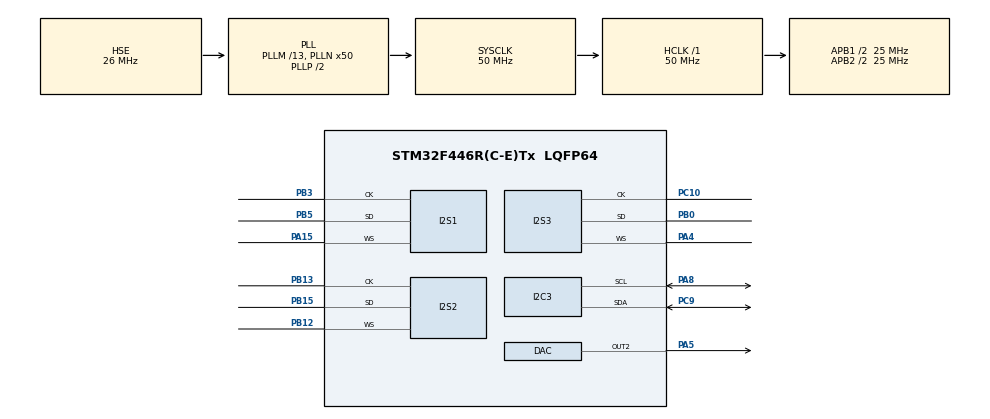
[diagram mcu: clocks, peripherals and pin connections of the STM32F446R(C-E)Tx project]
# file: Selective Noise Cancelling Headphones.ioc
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DAC.DAC_Trigger2=DAC_TRIGGER_NONE
Dma.DAC2.1.Direction=DMA_MEMORY_TO_PERIPH
Dma.DAC2.1.FIFOMode=DMA_FIFOMODE_DISABLE
Dma.DAC2.1.Instance=DMA1_Stream6
Dma.DAC2.1.MemDataAlignment=DMA_MDATAALIGN_HALFWORD
Dma.DAC2.1.MemInc=DMA_MINC_ENABLE
Dma.DAC2.1.Mode=DMA_CIRCULAR
Dma.DAC2.1.PeriphDataAlignment=DMA_PDATAALIGN_HALFWORD
Dma.DAC2.1.PeriphInc=DMA_PINC_DISABLE
Dma.DAC2.1.Priority=DMA_PRIORITY_HIGH
Dma.Request0=SPI3_RX
Dma.Request1=DAC2
Dma.Request2=SPI2_RX
Dma.SPI2_RX.2.Direction=DMA_PERIPH_TO_MEMORY
Dma.SPI2_RX.2.FIFOMode=DMA_FIFOMODE_DISABLE
Dma.SPI2_RX.2.Instance=DMA1_Stream3
Dma.SPI2_RX.2.MemDataAlignment=DMA_MDATAALIGN_HALFWORD
Dma.SPI2_RX.2.MemInc=DMA_MINC_ENABLE
Dma.SPI2_RX.2.Mode=DMA_CIRCULAR
Dma.SPI2_RX.2.PeriphDataAlignment=DMA_PDATAALIGN_HALFWORD
Dma.SPI2_RX.2.PeriphInc=DMA_PINC_DISABLE
Dma.SPI2_RX.2.Priority=DMA_PRIORITY_HIGH
Dma.SPI3_RX.0.Direction=DMA_PERIPH_TO_MEMORY
Dma.SPI3_RX.0.FIFOMode=DMA_FIFOMODE_DISABLE
Dma.SPI3_RX.0.Instance=DMA1_Stream0
Dma.SPI3_RX.0.MemDataAlignment=DMA_MDATAALIGN_HALFWORD
Dma.SPI3_RX.0.MemInc=DMA_MINC_ENABLE
Dma.SPI3_RX.0.Mode=DMA_CIRCULAR
Dma.SPI3_RX.0.PeriphDataAlignment=DMA_PDATAALIGN_HALFWORD
Dma.SPI3_RX.0.PeriphInc=DMA_PINC_DISABLE
Dma.SPI3_RX.0.Priority=DMA_PRIORITY_HIGH
I2S1.AudioFreq=I2S_AUDIOFREQ_48K
I2S1.DataFormat=I2S_DATAFORMAT_16B_EXTENDED
I2S1.ErrorAudioFreq=1.72 %
I2S1.FullDuplexMode=I2S_FULLDUPLEXMODE_DISABLE
I2S1.Instance=SPI$Index
I2S1.Mode=I2S_MODE_MASTER_RX
I2S1.RealAudioFreq=48.828 KHz
I2S1.VirtualMode=I2S_MODE_MASTER
I2S2.AudioFreq=I2S_AUDIOFREQ_48K
I2S2.DataFormat=I2S_DATAFORMAT_16B_EXTENDED
I2S2.ErrorAudioFreq=1.72 %
I2S2.FullDuplexMode=I2S_FULLDUPLEXMODE_DISABLE
I2S2.Instance=SPI$Index
I2S2.Mode=I2S_MODE_MASTER_RX
I2S2.RealAudioFreq=48.828 KHz
I2S2.VirtualMode=I2S_MODE_MASTER
I2S3.AudioFreq=I2S_AUDIOFREQ_48K
I2S3.DataFormat=I2S_DATAFORMAT_16B_EXTENDED
I2S3.ErrorAudioFreq=1.72 %
I2S3.FullDuplexMode=I2S_FULLDUPLEXMODE_DISABLE
I2S3.Instance=SPI$Index
I2S3.Mode=I2S_MODE_MASTER_RX
I2S3.RealAudioFreq=48.828 KHz
I2S3.VirtualMode=I2S_MODE_MASTER
Mcu.Family=STM32F4
Mcu.Name=STM32F446R(C-E)Tx
Mcu.Package=LQFP64
NVIC.DMA1_Stream0_IRQn=true\:0\:0\:false\:false\:true\:false\:true\:true
NVIC.DMA1_Stream3_IRQn=true\:0\:0\:false\:false\:true\:false\:true\:true
NVIC.DMA1_Stream6_IRQn=true\:0\:0\:false\:false\:true\:false\:true\:true
NVIC.PriorityGroup=NVIC_PRIORITYGROUP_4
NVIC.TIM2_IRQn=true\:15\:0\:false\:false\:true\:false\:true\:true
NVIC.TimeBase=TIM2_IRQn
NVIC.TimeBaseIP=TIM2
PA13.Mode=Serial_Wire
PA13.Signal=SYS_JTMS-SWDIO
PA14.Mode=Serial_Wire
PA14.Signal=SYS_JTCK-SWCLK
PA15.Mode=Half_Duplex_Master
PA15.Signal=I2S1_WS
PA4.Mode=Half_Duplex_Master
PA4.Signal=I2S3_WS
PA5.Signal=COMP_DAC2_group
PA8.Mode=I2C
PA8.Signal=I2C3_SCL
PB0.Mode=Half_Duplex_Master
PB0.Signal=I2S3_SD
PB12.Mode=Half_Duplex_Master
PB12.Signal=I2S2_WS
PB13.Mode=Half_Duplex_Master
PB13.Signal=I2S2_CK
PB15.Mode=Half_Duplex_Master
PB15.Signal=I2S2_SD
PB3.Mode=Half_Duplex_Master
PB3.Signal=I2S1_CK
PB5.Mode=Half_Duplex_Master
PB5.Signal=I2S1_SD
PC10.Mode=Half_Duplex_Master
PC10.Signal=I2S3_CK
PC9.Mode=I2C
PC9.Signal=I2C3_SDA
PH0-OSC_IN.Mode=HSE-External-Oscillator
PH0-OSC_IN.Signal=RCC_OSC_IN
PH1-OSC_OUT.Mode=HSE-External-Oscillator
PH1-OSC_OUT.Signal=RCC_OSC_OUT
ProjectManager.HeapSize=0x400
ProjectManager.StackSize=0x400
ProjectManager.TargetToolchain=STM32CubeIDE
RCC.AHBFreq_Value=50000000
RCC.APB1CLKDivider=RCC_HCLK_DIV2
RCC.APB1Freq_Value=25000000
RCC.APB1TimFreq_Value=50000000
RCC.APB2CLKDivider=RCC_HCLK_DIV2
RCC.APB2Freq_Value=25000000
RCC.APB2TimFreq_Value=50000000
RCC.CortexFreq_Value=50000000
RCC.HCLKFreq_Value=50000000
RCC.HSE_VALUE=26000000
RCC.PLLI2SM=13
RCC.PLLI2SN=50
RCC.PLLM=13
RCC.PLLN=50
RCC.PLLQ=4
RCC.PLLSourceVirtual=RCC_PLLSOURCE_HSE
RCC.SYSCLKFreq_VALUE=50000000
RCC.SYSCLKSource=RCC_SYSCLKSOURCE_PLLCLK
RCC.USBFreq_Value=25000000
RCC.VCOOutputFreq_Value=100000000
SH.COMP_DAC2_group.0=DAC_OUT2,DAC_OUT2
VP_SYS_VS_tim2.Mode=TIM2
board=custom

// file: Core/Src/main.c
/* USER CODE BEGIN Header */
/**
  ******************************************************************************
  * @file           : main.c
  * @brief          : Main program body
  ******************************************************************************
  * @attention
  *
  * Copyright (c) 2025 STMicroelectronics.
  * All rights reserved.
  *
  * This software is licensed under terms that can be found in the LICENSE file
  * in the root directory of this software component.
  * If no LICENSE file comes with this software, it is provided AS-IS.
  *
  ******************************************************************************
  */
/* USER CODE END Header */
#include "main.h"

/* USER CODE BEGIN Includes */

#include <stdio.h>
#include <stdlib.h>
#include "ADC.h"
#include "Delay.h"
#include "LowPass_FirstOrder.h"
#include "HighPass_FirstOrder.h"
#include "PeakingFilter.h"
#include "math.h"

/* USER CODE END Includes */

/* USER CODE BEGIN PM */

#define BUFFER_SIZE 128
#define INT16_TO_FLOAT (1.0f/32768.0f)
#define FLOAT_TO_INT16 32768.0f
#define SAMPLING_RATE 	48000
#define SIN_FREQ		1000
#define BUFFER_LENGTH 	SAMPLING_RATE / SIN_FREQ
#define VOLUME 50

/* USER CODE END PM */

DAC_HandleTypeDef hdac;
DMA_HandleTypeDef hdma_dac2;

I2C_HandleTypeDef hi2c3;

I2S_HandleTypeDef hi2s1;
I2S_HandleTypeDef hi2s2;
I2S_HandleTypeDef hi2s3;
DMA_HandleTypeDef hdma_spi2_rx;
DMA_HandleTypeDef hdma_spi3_rx;

/* USER CODE BEGIN PV */

int16_t inData[BUFFER_SIZE] __attribute__((aligned(4)));

static volatile int16_t *inBufPtr;

uint16_t dac_value;
uint16_t dataReadyFlag = 0;

//HighPass_FirstOrder hpFilt;
//LowPass_FirstOrder lpFilt;
EQ eq;
Delay dly;

/* USER CODE END PV */

void SystemClock_Config(void);
void PeriphCommonClock_Config(void);
static void MX_GPIO_Init(void);
static void MX_DMA_Init(void);
static void MX_DAC_Init(void);
static void MX_I2C3_Init(void);
static void MX_I2S3_Init(void);
static void MX_I2S2_Init(void);
static void MX_I2S1_Init(void);

/* USER CODE BEGIN 0 */

void HAL_I2S_RxHalfCpltCallback(I2S_HandleTypeDef *hi2s) {
	inBufPtr = &inData[0];
	dataReadyFlag = 1;

}

void HAL_I2S_RxCpltCallback(I2S_HandleTypeDef *hi2s) {
	inBufPtr = &inData[BUFFER_SIZE/2];
	dataReadyFlag = 1;
}

void processDataNoDelay() {

	float left;

	for (uint8_t n = 0; n < (BUFFER_SIZE/2) - 1; n += 1) {
		left = (inBufPtr[n] * INT16_TO_FLOAT);// + 0.0537;

		if (left > 1.0f) {
			left = 1.0f;
		}
		else if (left < -1.0f) {
			left = -1.0f;
		}

		//left = LowPass_FirstOrder_Update(&lpFilt, left);
		//left = HighPass_FirstOrder_Update(&hpFilt, left);

		dac_value = (int16_t)(left * 2047.0f * VOLUME) + 2048;
		HAL_DAC_SetValue(&hdac, DAC_CHANNEL_2, DAC_ALIGN_12B_R, dac_value);

	}

}

void processData(LowPass_FirstOrder *lpFilt, HighPass_FirstOrder *hpFilt) {

	static float left;
	static float right;
	static float rightDelayed;
	static float out;

	int16_t leftInverted;
	int16_t rightInverted;
	uint16_t leftInvertedShift;
	uint16_t rightInvertedShift;

	for (uint8_t n = 0; n < (BUFFER_SIZE/2) - 1; n += 2) {

		left = (inBufPtr[n] * INT16_TO_FLOAT);

		if (left > 1.0f) {
			left = 1.0f;
		}
		else if (left < -1.0f) {
			left = -1;

		}

		right = (inBufPtr[n+1] * INT16_TO_FLOAT);

		rightDelayed = Delay_Update(&dly, right);

		if (rightDelayed > 1.0f) {
			rightDelayed = 1.0f;
		}
		else if (rightDelayed < -1.0f) {
			rightDelayed = -1;
		}

		out = left - rightDelayed;

		out = LowPass_FirstOrder_Update(lpFilt, out);
		out = EQ_filter(&eq, out);
		out = out * VOLUME;

		if (out > 1.0f) {
			out = 1.0f;
		}
		else if (out < -1.0f) {
			out = -1;
		}

		dac_value = (uint16_t)(((int32_t)(out * 2047.0f)) + 2048);

		if (dac_value > 4095) {
			out = 4095;
		}

		HAL_DAC_SetValue(&hdac, DAC_CHANNEL_2, DAC_ALIGN_12B_R, dac_value);

	}

}

/* USER CODE END 0 */

int main(void)
{

  /* MCU Configuration--------------------------------------------------------*/

  /* Reset of all peripherals, Initializes the Flash interface and the Systick. */
  HAL_Init();

  /* USER CODE BEGIN Init */

  //__HAL_RCC_SYSCLK_CONFIG(RCC_CFGR_SWS_HSI);
  // HAL_NVIC_SetPriority(SysTick_IRQn, 0, 0);

  /* USER CODE END Init */

  /* Configure the system clock */
  SystemClock_Config();

  /* Configure the peripherals common clocks */
  PeriphCommonClock_Config();

  /* USER CODE BEGIN SysInit */
  //HAL_NVIC_EnableIRQ(SysTick_IRQn);

  /* USER CODE END SysInit */

  /* Initialize all configured peripherals */
  MX_GPIO_Init();
  MX_DMA_Init();
  MX_DAC_Init();
  MX_I2C3_Init();
  MX_I2S3_Init();
  MX_I2S2_Init();
  MX_I2S1_Init();
  /* USER CODE BEGIN 2 */

/*
 *
 */

  //DWT_Init();
  HAL_DAC_Start(&hdac, DAC_CHANNEL_2);
  HAL_I2S_Receive_DMA(&hi2s3, (uint16_t *)inData, BUFFER_SIZE);

  // 500 hz: delay = 1 ms
  float delayTime = 0.4081632653;;
  Delay_Init(&dly, delayTime, 1, 0, SAMPLING_RATE);

  LowPass_FirstOrder *lpFilt = (LowPass_FirstOrder*)malloc(sizeof(LowPass_FirstOrder));
  HighPass_FirstOrder *hpFilt = (HighPass_FirstOrder*)malloc(sizeof(HighPass_FirstOrder));

  if (!lpFilt || !hpFilt) {
      Error_Handler();  // Or handle it gracefully
  }

  LowPass_FirstOrder_Init(lpFilt, 2000.0f, SAMPLING_RATE);
  EQ_init(&eq, SAMPLING_RATE);
  EQ_setParam(&eq, 200, 5, 80);

  /* USER CODE END 2 */

  /* Infinite loop */
  while (1)
  {

    /* USER CODE BEGIN 3 */

	   if (dataReadyFlag) {
		   dataReadyFlag = 0;
		   processData(lpFilt, hpFilt);

	    }

	  }

  /* USER CODE END 3 */
}

void SystemClock_Config(void)
{
  RCC_OscInitTypeDef RCC_OscInitStruct = {0};
  RCC_ClkInitTypeDef RCC_ClkInitStruct = {0};

  /** Configure the main internal regulator output voltage
  */
  __HAL_RCC_PWR_CLK_ENABLE();
  __HAL_PWR_VOLTAGESCALING_CONFIG(PWR_REGULATOR_VOLTAGE_SCALE3);

  /** Initializes the RCC Oscillators according to the specified parameters
  * in the RCC_OscInitTypeDef structure.
  */
  RCC_OscInitStruct.OscillatorType = RCC_OSCILLATORTYPE_HSE;
  RCC_OscInitStruct.HSEState = RCC_HSE_ON;
  RCC_OscInitStruct.PLL.PLLState = RCC_PLL_ON;
  RCC_OscInitStruct.PLL.PLLSource = RCC_PLLSOURCE_HSE;
  RCC_OscInitStruct.PLL.PLLM = 13;
  RCC_OscInitStruct.PLL.PLLN = 50;
  RCC_OscInitStruct.PLL.PLLP = RCC_PLLP_DIV2;
  RCC_OscInitStruct.PLL.PLLQ = 4;
  RCC_OscInitStruct.PLL.PLLR = 2;
  if (HAL_RCC_OscConfig(&RCC_OscInitStruct) != HAL_OK)
  {
    Error_Handler();
  }

  /** Initializes the CPU, AHB and APB buses clocks
  */
  RCC_ClkInitStruct.ClockType = RCC_CLOCKTYPE_HCLK|RCC_CLOCKTYPE_SYSCLK
                              |RCC_CLOCKTYPE_PCLK1|RCC_CLOCKTYPE_PCLK2;
  RCC_ClkInitStruct.SYSCLKSource = RCC_SYSCLKSOURCE_PLLCLK;
  RCC_ClkInitStruct.AHBCLKDivider = RCC_SYSCLK_DIV1;
  RCC_ClkInitStruct.APB1CLKDivider = RCC_HCLK_DIV2;
  RCC_ClkInitStruct.APB2CLKDivider = RCC_HCLK_DIV2;

  if (HAL_RCC_ClockConfig(&RCC_ClkInitStruct, FLASH_LATENCY_1) != HAL_OK)
  {
    Error_Handler();
  }
}

void PeriphCommonClock_Config(void)
{
  RCC_PeriphCLKInitTypeDef PeriphClkInitStruct = {0};

  /** Initializes the peripherals clock
  */
  PeriphClkInitStruct.PeriphClockSelection = RCC_PERIPHCLK_I2S_APB1|RCC_PERIPHCLK_I2S_APB2;
  PeriphClkInitStruct.PLLI2S.PLLI2SN = 50;
  PeriphClkInitStruct.PLLI2S.PLLI2SP = RCC_PLLI2SP_DIV2;
  PeriphClkInitStruct.PLLI2S.PLLI2SM = 13;
  PeriphClkInitStruct.PLLI2S.PLLI2SR = 2;
  PeriphClkInitStruct.PLLI2S.PLLI2SQ = 2;
  PeriphClkInitStruct.PLLI2SDivQ = 1;
  PeriphClkInitStruct.I2sApb2ClockSelection = RCC_I2SAPB2CLKSOURCE_PLLI2S;
  PeriphClkInitStruct.I2sApb1ClockSelection = RCC_I2SAPB1CLKSOURCE_PLLI2S;
  if (HAL_RCCEx_PeriphCLKConfig(&PeriphClkInitStruct) != HAL_OK)
  {
    Error_Handler();
  }
}

static void MX_DAC_Init(void)
{

  DAC_ChannelConfTypeDef sConfig = {0};

  /** DAC Initialization
  */
  hdac.Instance = DAC;
  if (HAL_DAC_Init(&hdac) != HAL_OK)
  {
    Error_Handler();
  }

  /** DAC channel OUT2 config
  */
  sConfig.DAC_Trigger = DAC_TRIGGER_NONE;
  sConfig.DAC_OutputBuffer = DAC_OUTPUTBUFFER_ENABLE;
  if (HAL_DAC_ConfigChannel(&hdac, &sConfig, DAC_CHANNEL_2) != HAL_OK)
  {
    Error_Handler();
  }

}

static void MX_I2C3_Init(void)
{

  hi2c3.Instance = I2C3;
  hi2c3.Init.ClockSpeed = 100000;
  hi2c3.Init.DutyCycle = I2C_DUTYCYCLE_2;
  hi2c3.Init.OwnAddress1 = 0;
  hi2c3.Init.AddressingMode = I2C_ADDRESSINGMODE_7BIT;
  hi2c3.Init.DualAddressMode = I2C_DUALADDRESS_DISABLE;
  hi2c3.Init.OwnAddress2 = 0;
  hi2c3.Init.GeneralCallMode = I2C_GENERALCALL_DISABLE;
  hi2c3.Init.NoStretchMode = I2C_NOSTRETCH_DISABLE;
  if (HAL_I2C_Init(&hi2c3) != HAL_OK)
  {
    Error_Handler();
  }

}

static void MX_I2S1_Init(void)
{

  hi2s1.Instance = SPI1;
  hi2s1.Init.Mode = I2S_MODE_MASTER_RX;
  hi2s1.Init.Standard = I2S_STANDARD_PHILIPS;
  hi2s1.Init.DataFormat = I2S_DATAFORMAT_16B_EXTENDED;
  hi2s1.Init.MCLKOutput = I2S_MCLKOUTPUT_DISABLE;
  hi2s1.Init.AudioFreq = I2S_AUDIOFREQ_48K;
  hi2s1.Init.CPOL = I2S_CPOL_LOW;
  hi2s1.Init.ClockSource = I2S_CLOCK_PLL;
  hi2s1.Init.FullDuplexMode = I2S_FULLDUPLEXMODE_DISABLE;
  if (HAL_I2S_Init(&hi2s1) != HAL_OK)
  {
    Error_Handler();
  }

}

static void MX_I2S2_Init(void)
{

  hi2s2.Instance = SPI2;
  hi2s2.Init.Mode = I2S_MODE_MASTER_RX;
  hi2s2.Init.Standard = I2S_STANDARD_PHILIPS;
  hi2s2.Init.DataFormat = I2S_DATAFORMAT_16B_EXTENDED;
  hi2s2.Init.MCLKOutput = I2S_MCLKOUTPUT_DISABLE;
  hi2s2.Init.AudioFreq = I2S_AUDIOFREQ_48K;
  hi2s2.Init.CPOL = I2S_CPOL_LOW;
  hi2s2.Init.ClockSource = I2S_CLOCK_PLL;
  hi2s2.Init.FullDuplexMode = I2S_FULLDUPLEXMODE_DISABLE;
  if (HAL_I2S_Init(&hi2s2) != HAL_OK)
  {
    Error_Handler();
  }

}

static void MX_I2S3_Init(void)
{

  hi2s3.Instance = SPI3;
  hi2s3.Init.Mode = I2S_MODE_MASTER_RX;
  hi2s3.Init.Standard = I2S_STANDARD_PHILIPS;
  hi2s3.Init.DataFormat = I2S_DATAFORMAT_16B_EXTENDED;
  hi2s3.Init.MCLKOutput = I2S_MCLKOUTPUT_DISABLE;
  hi2s3.Init.AudioFreq = I2S_AUDIOFREQ_48K;
  hi2s3.Init.CPOL = I2S_CPOL_LOW;
  hi2s3.Init.ClockSource = I2S_CLOCK_PLL;
  hi2s3.Init.FullDuplexMode = I2S_FULLDUPLEXMODE_DISABLE;
  if (HAL_I2S_Init(&hi2s3) != HAL_OK)
  {
    Error_Handler();
  }

}

static void MX_DMA_Init(void)
{

  /* DMA controller clock enable */
  __HAL_RCC_DMA1_CLK_ENABLE();

  /* DMA interrupt init */
  /* DMA1_Stream0_IRQn interrupt configuration */
  HAL_NVIC_SetPriority(DMA1_Stream0_IRQn, 0, 0);
  HAL_NVIC_EnableIRQ(DMA1_Stream0_IRQn);
  /* DMA1_Stream3_IRQn interrupt configuration */
  HAL_NVIC_SetPriority(DMA1_Stream3_IRQn, 0, 0);
  HAL_NVIC_EnableIRQ(DMA1_Stream3_IRQn);
  /* DMA1_Stream6_IRQn interrupt configuration */
  HAL_NVIC_SetPriority(DMA1_Stream6_IRQn, 0, 0);
  HAL_NVIC_EnableIRQ(DMA1_Stream6_IRQn);

}

static void MX_GPIO_Init(void)
{
  GPIO_InitTypeDef GPIO_InitStruct = {0};

  /* GPIO Ports Clock Enable */
  __HAL_RCC_GPIOH_CLK_ENABLE();
  __HAL_RCC_GPIOA_CLK_ENABLE();
  __HAL_RCC_GPIOB_CLK_ENABLE();
  __HAL_RCC_GPIOC_CLK_ENABLE();

  /*Configure GPIO pin Output Level */
  HAL_GPIO_WritePin(GPIOC, GPIO_PIN_6, GPIO_PIN_RESET);

  /*Configure GPIO pin : PC6 */
  GPIO_InitStruct.Pin = GPIO_PIN_6;
  GPIO_InitStruct.Mode = GPIO_MODE_OUTPUT_PP;
  GPIO_InitStruct.Pull = GPIO_NOPULL;
  GPIO_InitStruct.Speed = GPIO_SPEED_FREQ_LOW;
  HAL_GPIO_Init(GPIOC, &GPIO_InitStruct);

}

/* USER CODE BEGIN 4 */
/*
int _write(int file, char *ptr, int len) {
	int DataIdx;

	for (DataIdx = 0; DataIdx < len; DataIdx++) {
		ITM_SendChar(*ptr++);
	}
	return len;
}
*/

/* USER CODE END 4 */

void HAL_TIM_PeriodElapsedCallback(TIM_HandleTypeDef *htim)
{
  if (htim->Instance == TIM2) {
    HAL_IncTick();
  }
}

void Error_Handler(void)
{
  __disable_irq();
  while (1)
  {
  }
}
